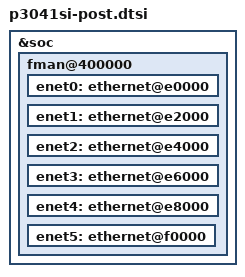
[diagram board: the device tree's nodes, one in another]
// SPDX-License-Identifier: (GPL-2.0+ OR BSD-3-Clause)
/*
 * P3041 Silicon/SoC Device Tree Source (post include)
 *
 * Copyright 2011 - 2015 Freescale Semiconductor Inc.
 * Copyright 2020 NXP
 *
 */

&soc {

/include/ "qoriq-clockgen1.dtsi"
/include/ "qoriq-gpio-0.dtsi"
/include/ "qoriq-sec4.2-0.dtsi"

/* include used FMan blocks */
/include/ "qoriq-fman-0.dtsi"
/include/ "qoriq-fman-0-1g-0.dtsi"
/include/ "qoriq-fman-0-1g-1.dtsi"
/include/ "qoriq-fman-0-1g-2.dtsi"
/include/ "qoriq-fman-0-1g-3.dtsi"
/include/ "qoriq-fman-0-1g-4.dtsi"
/include/ "qoriq-fman-0-10g-0.dtsi"
	fman@400000 {
		enet0: ethernet@e0000 {
		};

		enet1: ethernet@e2000 {
		};

		enet2: ethernet@e4000 {
		};

		enet3: ethernet@e6000 {
		};

		enet4: ethernet@e8000 {
		};

		enet5: ethernet@f0000 {
		};
	};
};
